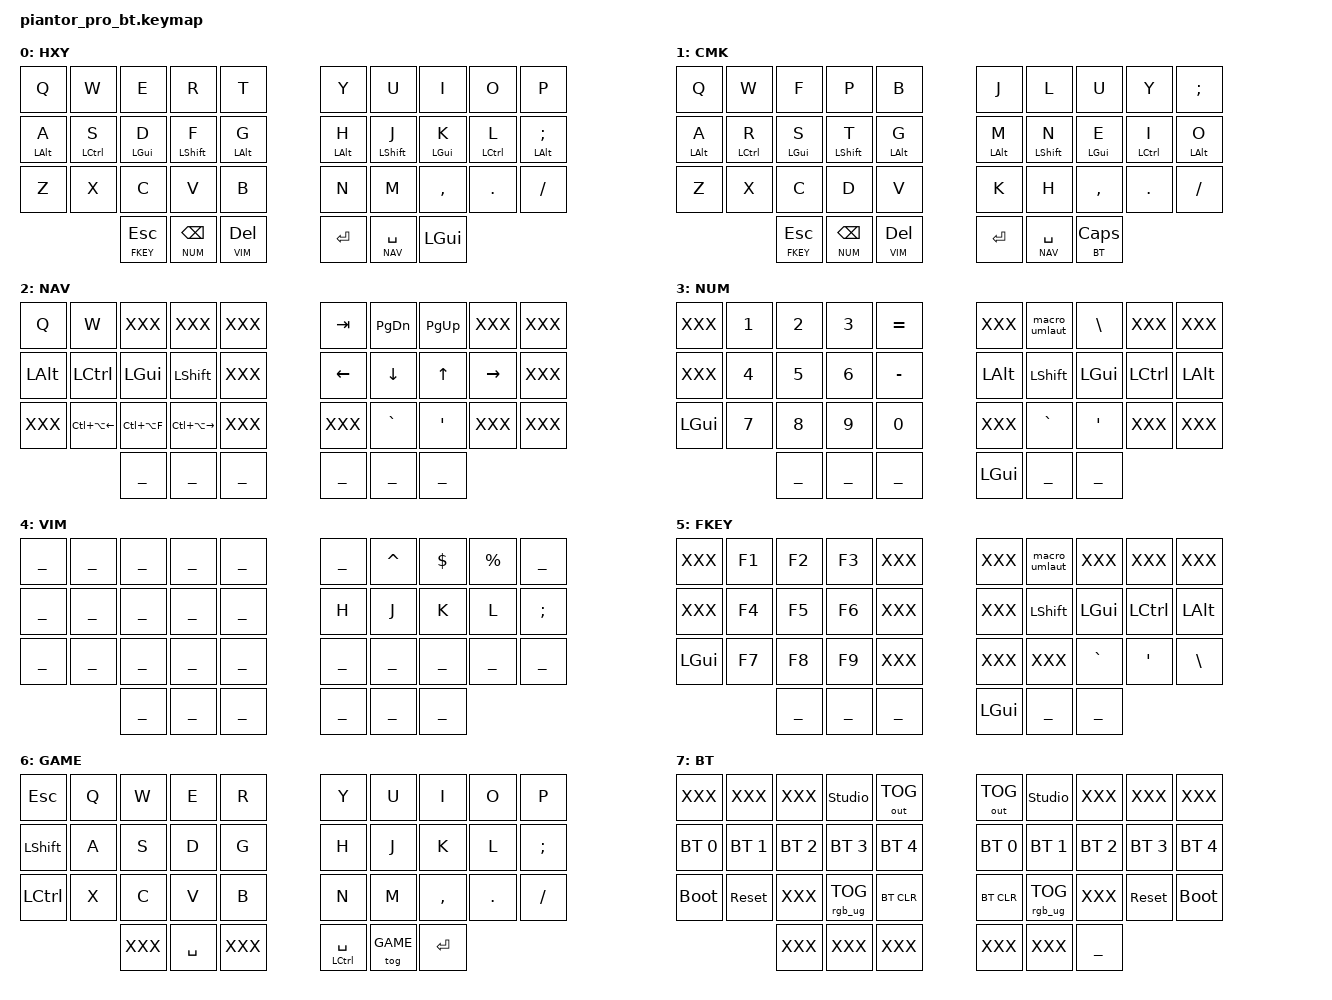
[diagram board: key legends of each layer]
#include <behaviors.dtsi>
#include <dt-bindings/zmk/keys.h>
#include <dt-bindings/zmk/bt.h>
#include <dt-bindings/zmk/outputs.h>
#include <dt-bindings/zmk/rgb.h>
#include "piantor_pro_bt/keys.h"

/ {
    chosen {
        zmk,physical-layout = &five_col_layout;
    };
};

&sk {
  release-after-ms = <STICKY_KEY_TIMEOUT>;
};

&caps_word {
  continue-list = <UNDERSCORE MINUS BACKSPACE>;
};

/ {
  combos {
    #include "piantor_pro_bt/combos.dtsi"
  };

  macros {
   #include "piantor_pro_bt/macros.dtsi"
  };

  behaviors {

    skq: sticky_key_quick_release {
      compatible = "zmk,behavior-sticky-key";
      label = "STICKY_KEY_QUICK_RELEASE";
      #binding-cells = <1>;
      bindings = <&kp>;
      quick-release;
      release-after-ms = <STICKY_KEY_TIMEOUT>;
    };

    // Sticky key on tap, normal key on hold
    // Useful for modifier-clicking without the modifier remaining active
    nk: not_so_sticky_key {
      compatible = "zmk,behavior-hold-tap";
      label = "NOT_SO_STICKY_KEY";
      #binding-cells = <2>;
      tapping_term_ms = <200>;
      flavor = "tap-preferred";
      bindings = <&kp>, <&sk>;
    };

    // A hold-tap that activates without delay (like `&mo`)
    mo_tap: mo_with_tap {
      compatible = "zmk,behavior-hold-tap";
      label = "MO_WITH_TAP";
      #binding-cells = <2>;
      tapping_term_ms = <0>;
      retro-tap;
      flavor = "hold-preferred";
      bindings = <&mo>, <&kp>;
    };

    gqt: global-quick-tap {
      compatible = "zmk,behavior-hold-tap";
      label = "GLOBAL_QUICK_TAP";
      #binding-cells = <2>;
      flavor = "tap-preferred";
      tapping-term-ms = <200>;
      quick-tap-ms = <125>;
      global-quick-tap;
      bindings = <&kp>, <&kp>;
   };
  };

  /*
    LAYERS
      &mo - Momentary Layer switch
      &lt - Layer Tap - Enable layer when held, key when tapped
      &to - Enable layer permanently, disables all others but base
      &tog - Toggle layer until manually disabled
    
    OTHERS
      &kp - Key press, nothing more
      &mt - Mod-Tap - Key if held, different key if tapped
      &sk - Sticky Key - Key is pressed until another key is pressed (e.g sticky shift)
      &sl - Sticky layer - Same as &sk but with layers
  */
                                                     
  keymap {
    compatible = "zmk,keymap";

    base_layer {
      label = "HXY";
      bindings = <
        // ╭─────────────┬─────────────┬─────────────┬─────────────┬─────────────╮   ╭─────────────┬─────────────┬─────────────┬─────────────┬─────────────╮
             &kp Q         &kp W         &kp E        &kp R         &kp T              &kp Y         &kp U         &kp I         &kp O         &kp P
        // ├─────────────┼─────────────┼─────────────┼─────────────┼─────────────┤   ├─────────────┼─────────────┼─────────────┼─────────────┼─────────────┤
            &gqt LALT A   &gqt LCTRL S  &gqt LGUI D   &gqt LSHIFT F   &gqt LALT G      &gqt LALT H   &gqt LSHIFT J   &gqt LGUI K   &gqt LCTRL L    &gqt LALT SEMI 
        // ├─────────────┼─────────────┼─────────────┼─────────────┼─────────────┤   ├─────────────┼─────────────┼─────────────┼─────────────┼─────────────┤
             &kp Z         &kp X         &kp C         &kp V          &kp B            &kp N         &kp M         &kp COMMA     &kp DOT      &kp SLASH
        // ╰─────────────┴─────────────┴─────────────┼─────────────┼─────────────┤   ├─────────────┼─────────────┼─────────────┴─────────────┴─────────────╯
                                         &lt FKEY ESC   &lt NUM BSPC   &lt VIM DEL     &kp ENTER     &lt NAV SPACE  &kp LGUI
        //                              ╰────────────┴─────────────┴─────────────╯   ╰─────────────┴─────────────┴─────────────╯
      >;
    };

    colemak_layer {
      label = "CMK";
      bindings = <
        // ╭─────────────┬─────────────┬─────────────┬─────────────┬─────────────╮   ╭─────────────┬─────────────┬─────────────┬─────────────┬─────────────╮
             &kp Q         &kp W         &kp F         &kp P         &kp B              &kp J         &kp L         &kp U         &kp Y         &kp SEMI
        // ├─────────────┼─────────────┼─────────────┼─────────────┼─────────────┤   ├─────────────┼─────────────┼─────────────┼─────────────┼─────────────┤
            &gqt LALT A   &gqt LCTRL R  &gqt LGUI S   &gqt LSHIFT T   &gqt LALT G      &gqt LALT M   &gqt LSHIFT N   &gqt LGUI E   &gqt LCTRL I    &gqt LALT O
        // ├─────────────┼─────────────┼─────────────┼─────────────┼─────────────┤   ├─────────────┼─────────────┼─────────────┼─────────────┼─────────────┤
             &kp Z         &kp X         &kp C         &kp D          &kp V            &kp K         &kp H         &kp COMMA     &kp DOT      &kp SLASH
        // ╰─────────────┴─────────────┴─────────────┼─────────────┼─────────────┤   ├─────────────┼─────────────┼─────────────┴─────────────┴─────────────╯
                                         &lt FKEY ESC   &lt NUM BSPC   &lt VIM DEL     &kp ENTER     &lt NAV SPACE  &lt BT CAPS
        //                              ╰────────────┴─────────────┴─────────────╯   ╰─────────────┴─────────────┴─────────────╯
      >;
    };

    nav_layer {
      label = "NAV";
      bindings = <
        // ╭─────────────┬─────────────┬─────────────┬─────────────┬─────────────╮   ╭─────────────┬─────────────┬─────────────┬─────────────┬─────────────╮
             &kp Q         &kp W          XXX           XXX           XXX              &kp TAB       &kp PG_DN     &kp PG_UP     XXX           XXX
        // ├─────────────┼─────────────┼─────────────┼─────────────┼─────────────┤   ├─────────────┼─────────────┼─────────────┼─────────────┼─────────────┤
             &kp LALT      &kp LCTRL     &kp LGUI      &kp LSHIFT    XXX               &kp LEFT      &kp DOWN      &kp UP        &kp RIGHT     XXX 
        // ├─────────────┼─────────────┼─────────────┼─────────────┼─────────────┤   ├─────────────┼─────────────┼─────────────┼─────────────┼─────────────┤
             XXX           &kp LC(LA(LEFT)) &kp LC(LA(F)) &kp LC(LA(RIGHT))  XXX       XXX            &kp GRAVE    &kp SQT       XXX           XXX 
        // ╰─────────────┴─────────────┴─────────────┼─────────────┼─────────────┤   ├─────────────┼─────────────┼─────────────┴─────────────┴─────────────╯
                                          ___          ___           ___               ___           ___			___
        //                             ╰─────────────┴─────────────┴─────────────╯   ╰─────────────┴─────────────┴─────────────╯
      >;
    };
    
    num_layer {
      label = "NUM";
      bindings = <
        // ╭─────────────┬─────────────┬─────────────┬─────────────┬─────────────╮   ╭─────────────┬─────────────┬─────────────┬─────────────┬─────────────╮
            XXX            &kp N1        &kp N2        &kp N3        &kp EQUAL         XXX            &macro_umlaut  &kp BACKSLASH  XXX         XXX           
        // ├─────────────┼─────────────┼─────────────┼─────────────┼─────────────┤   ├─────────────┼─────────────┼─────────────┼─────────────┼─────────────┤
            XXX            &kp N4        &kp N5        &kp N6        &kp MINUS         &kp LALT       &kp LSHIFT     &kp LGUI     &kp LCTRL     &kp LALT             
        // ├─────────────┼─────────────┼─────────────┼─────────────┼─────────────┤   ├─────────────┼─────────────┼─────────────┼─────────────┼─────────────┤
            &kp LGUI       &kp N7        &kp N8        &kp N9        &kp N0            XXX            &kp GRAVE    &kp SQT       XXX            XXX 
        // ╰─────────────┴─────────────┴─────────────┼─────────────┼─────────────┤   ├─────────────┼─────────────┼─────────────┴─────────────┴─────────────╯
                                         ___            ___           ___               &kp LGUI        ___ 		   ___
        //                             ╰─────────────┴─────────────┴─────────────╯   ╰─────────────┴─────────────┴─────────────╯
      >;
    };
  
    vim_layer {
      label = "VIM";
      bindings = <
        // ╭─────────────┬─────────────┬─────────────┬─────────────┬─────────────╮   ╭─────────────┬─────────────┬─────────────┬─────────────┬─────────────╮
             ___           ___           ___           ___           ___                ___           &kp CARET     &kp DOLLAR    &kp PERCENT   ___
        // ├─────────────┼─────────────┼─────────────┼─────────────┼─────────────┤   ├─────────────┼─────────────┼─────────────┼─────────────┼─────────────┤
             ___           ___           ___           ___           ___               &kp H         &kp J         &kp K         &kp L         &kp SEMI 
        // ├─────────────┼─────────────┼─────────────┼─────────────┼─────────────┤   ├─────────────┼─────────────┼─────────────┼─────────────┼─────────────┤
             ___           ___           ___           ___            ___              ___           ___           ___           ___           ___  
        // ╰─────────────┴─────────────┴─────────────┼─────────────┼─────────────┤   ├─────────────┼─────────────┼─────────────┴─────────────┴─────────────╯
                                          ___          ___           ___               ___           ___			___
        //                              ╰────────────┴─────────────┴─────────────╯   ╰─────────────┴─────────────┴─────────────╯
      >;
    };

    fkey_layer {
      label = "FKEY";
      bindings = <
        // ╭─────────────┬─────────────┬─────────────┬─────────────┬─────────────╮   ╭─────────────┬─────────────┬─────────────┬─────────────┬─────────────╮
            XXX            &kp F1        &kp F2        &kp F3        XXX               XXX            &macro_umlaut  XXX          XXX           XXX           
        // ├─────────────┼─────────────┼─────────────┼─────────────┼─────────────┤   ├─────────────┼─────────────┼─────────────┼─────────────┼─────────────┤
            XXX            &kp F4        &kp F5        &kp F6        XXX               XXX            &kp LSHIFT     &kp LGUI     &kp LCTRL      &kp LALT             
        // ├─────────────┼─────────────┼─────────────┼─────────────┼─────────────┤   ├─────────────┼─────────────┼─────────────┼─────────────┼─────────────┤
            &kp LGUI       &kp F7        &kp F8        &kp F9        XXX               XXX            XXX            &kp GRAVE    &kp SQT       &kp BACKSLASH 
        // ╰─────────────┴─────────────┴─────────────┼─────────────┼─────────────┤   ├─────────────┼─────────────┼─────────────┴─────────────┴─────────────╯
                                         ___            ___           ___               &kp LGUI        ___ 		   ___
        //                             ╰─────────────┴─────────────┴─────────────╯   ╰─────────────┴─────────────┴─────────────╯
      >;
    };

    game_layer {
      label = "GAME";
      bindings = <
             &kp ESC         &kp Q         &kp W         &kp E         &kp R              &kp Y         &kp U         &kp I         &kp O         &kp P
             &kp LSHIFT      &kp A         &kp S         &kp D         &kp G             &kp H         &kp J         &kp K        &kp L         &kp SEMI
             &kp LCTRL       &kp X         &kp C         &kp V         &kp B             &kp N         &kp M         &kp COMMA     &kp DOT      &kp SLASH
                                            XXX         &kp SPACE      XXX             &mt LCTRL SPACE   &tog GAME	    &kp ENTER
      >;
    };

    bt_layer {
      label = "BT";
      bindings = <
        // ╭─────────────┬─────────────┬─────────────┬─────────────┬─────────────╮   ╭─────────────┬─────────────┬─────────────┬─────────────┬─────────────╮
             XXX           XXX           XXX          &studio_unlock &out OUT_TOG      &out OUT_TOG &studio_unlock XXX           XXX           XXX
        // ├─────────────┼─────────────┼─────────────┼─────────────┼─────────────┤   ├─────────────┼─────────────┼─────────────┼─────────────┼─────────────┤
            &bt BT_SEL 0  &bt BT_SEL 1  &bt BT_SEL 2  &bt BT_SEL 3  &bt BT_SEL 4       &bt BT_SEL 0  &bt BT_SEL 1  &bt BT_SEL 2  &bt BT_SEL 3  &bt BT_SEL 4
        // ├─────────────┼─────────────┼─────────────┼─────────────┼─────────────┤   ├─────────────┼─────────────┼─────────────┼─────────────┼─────────────┤
            &bootloader   &sys_reset    XXX       &rgb_ug RGB_TOG   &bt BT_CLR         &bt BT_CLR    &rgb_ug RGB_TOG XXX          &sys_reset    &bootloader
        // ╰─────────────┴─────────────┴─────────────┼─────────────┼─────────────┤   ├─────────────┼─────────────┼─────────────┴─────────────┴─────────────╯
                                          XXX          XXX           XXX               XXX           XXX           ___
        //                              ╰────────────┴─────────────┴─────────────╯   ╰─────────────┴─────────────┴─────────────╯
      >;
    };

  };
};
